# CAPTIVATE_445_inst4 register map
Vendor: Texas Instruments
Peripheral module from a debugger description file (folder msp430).
Registers are 16-bit, read-write, no defined reset value unless marked. A register's access mark holds for its fields unless they carry their own. Offsets are as the file gives them; lines under a group give offsets from that group; [hi:lo] are bit positions; {n}, {i} and the like mark numbered series; 'fields as' and 'values as' point back to an identical list; <NAME> marks a mode.

## CAPTIVATE
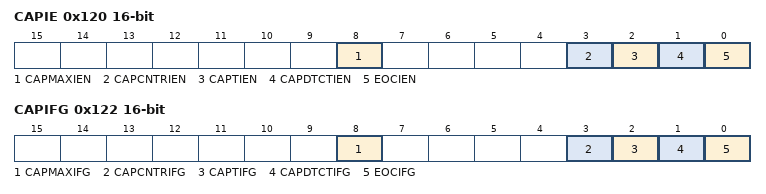
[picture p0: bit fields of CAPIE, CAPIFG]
0x120 CAPIE — Captivate Interrupt Enable Register
  [all] fields
    0=Interrupt disabled; 1=Interrupt enabled
  [8] CAPMAXIEN — Captivate maximum count interrupt enable
  [3] CAPCNTRIEN — Captivate Conversion Counter interrupt enable
  [2] CAPTIEN — Captivate Timer interrupt enable
  [1] CAPDTCTIEN — Captivate detection interrupt enable
  [0] EOCIEN — End of conversion interrupt enable When enabled, an interrupt is called when EOCIFG = 1; that is, at the end of each conversion. EOCIFG must be cleared during the interrupt service routine.
0x120 CAPIE — Captivate Interrupt Enable Register
  fields as CAPIE
0x122 CAPIFG — Captivate Interrupt Flag Register
  [8] CAPMAXIFG — Captivate maximum count interrupt flag
    0=Maximum count not reached; 1=Maximum count reached
  [3] CAPCNTRIFG — specified number of conversion have been reached
    0=No interrupt pending; 1=Interrupt pending
  [2] CAPTIFG — Captivate timer interrupt flag
    0=No interrupt pending; 1=Interrupt pending
  [1] CAPDTCTIFG — Captivate detection interrupt flag
    0=No interrupt pending; 1=Interrupt pending
  [0] EOCIFG — End of conversion interrupt flag This bit is set by hardware when each of the enabled CRx channels has finished converting and its results are ready. This bit is cleared by hardware when a conversion is launched (when CIPF becomes 1) or when CAPPWR = 0. If EOCITEN = 1, the Captivate interrupt occurs when EOCIFG transitions to 1. EOCIFG must be cleared by software before exiting the interrupt service routine.
    0=No end of conversion has occurred; 1=End of conversion has occurred
0x122 CAPIFG — Captivate Interrupt Flag Register
  fields as CAPIFG
0x124 CAPIV ro — Captivate Interrupt Vector Register
  [15:0] CAPIV — Captivate Interrupt vector value. It generates an value that can be used as address offset for fast interrupt service routine handling. 000Ch to FFFEh = Reserved Read will clear highest priority interrupt. Write will clear all pending interrupts.
    0=No interrupt pending; 2=Interrupt source: End of conversion interrupt, Flag = EOCIFG; 4=Interrupt source: Detection interrupt, Flag = CAPDTCTIFG; 6=Interrupt source: Captivate Timer interrupt, Flag = CAPTIFG; 8=Interrupt source: Captivate Counter interrupt, Flag = CAPCNTRIFG; 10=Interrupt source: max count value reached, Flag = CAPMAXIFG
0x124 CAPIV ro — Captivate Interrupt Vector Register
  fields as CAPIV
